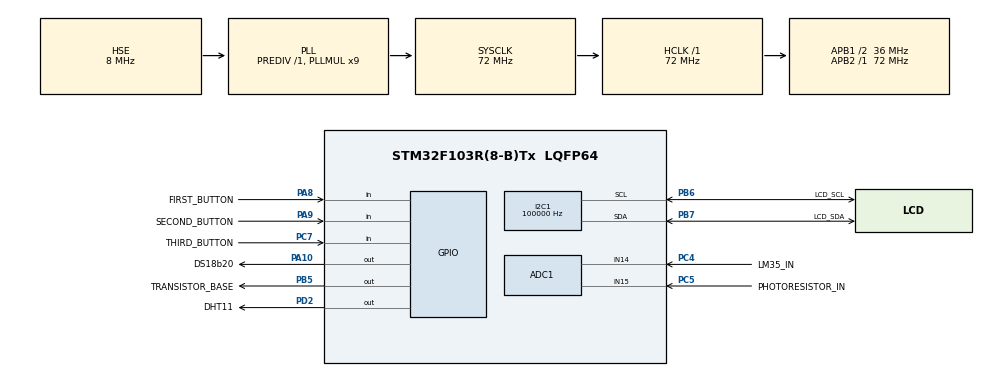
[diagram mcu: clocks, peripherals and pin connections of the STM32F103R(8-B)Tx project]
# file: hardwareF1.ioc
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ADC1.Channel-2\#ChannelRegularConversion=ADC_CHANNEL_14
ADC1.Channel-3\#ChannelRegularConversion=ADC_CHANNEL_TEMPSENSOR
ADC1.Channel-4\#ChannelRegularConversion=ADC_CHANNEL_15
ADC1.ContinuousConvMode=ENABLE
ADC1.DataAlign=ADC_DATAALIGN_RIGHT
ADC1.NbrOfConversion=3
ADC1.NbrOfConversionFlag=1
ADC1.Rank-2\#ChannelRegularConversion=1
ADC1.Rank-3\#ChannelRegularConversion=2
ADC1.Rank-4\#ChannelRegularConversion=3
ADC1.SamplingTime-2\#ChannelRegularConversion=ADC_SAMPLETIME_239CYCLES_5
ADC1.SamplingTime-3\#ChannelRegularConversion=ADC_SAMPLETIME_239CYCLES_5
ADC1.SamplingTime-4\#ChannelRegularConversion=ADC_SAMPLETIME_239CYCLES_5
ADC1.master=1
Dma.ADC1.0.Direction=DMA_PERIPH_TO_MEMORY
Dma.ADC1.0.Instance=DMA1_Channel1
Dma.ADC1.0.MemDataAlignment=DMA_MDATAALIGN_WORD
Dma.ADC1.0.MemInc=DMA_MINC_ENABLE
Dma.ADC1.0.Mode=DMA_CIRCULAR
Dma.ADC1.0.PeriphDataAlignment=DMA_PDATAALIGN_HALFWORD
Dma.ADC1.0.PeriphInc=DMA_PINC_DISABLE
Dma.ADC1.0.Priority=DMA_PRIORITY_LOW
Dma.Request0=ADC1
I2C1.AddressingMode=I2C_ADDRESSINGMODE_7BIT
I2C1.ClockSpeed=100000
I2C1.I2C_Mode=I2C_Standard
Mcu.Family=STM32F1
Mcu.Name=STM32F103R(8-B)Tx
Mcu.Package=LQFP64
NVIC.DMA1_Channel1_IRQn=true\:0\:0\:false\:false\:true\:false\:true
NVIC.PriorityGroup=NVIC_PRIORITYGROUP_4
NVIC.TIM3_IRQn=true\:0\:0\:false\:false\:true\:true\:true
PA10.GPIO_Label=DS18b20
PA10.Signal=GPIO_Output
PA13.Mode=JTAG_4_pins
PA13.Signal=SYS_JTMS-SWDIO
PA14.Mode=JTAG_4_pins
PA14.Signal=SYS_JTCK-SWCLK
PA15.Mode=JTAG_4_pins
PA15.Signal=SYS_JTDI
PA8.GPIO_Label=FIRST_BUTTON
PA8.Signal=GPIO_Input
PA9.GPIO_Label=SECOND_BUTTON
PA9.Signal=GPIO_Input
PB3.Mode=JTAG_4_pins
PB3.Signal=SYS_JTDO-TRACESWO
PB5.GPIO_Label=TRANSISTOR_BASE
PB5.Signal=GPIO_Output
PB6.GPIO_Label=LCD_SCL
PB6.Mode=I2C
PB6.Signal=I2C1_SCL
PB7.GPIO_Label=LCD_SDA
PB7.Mode=I2C
PB7.Signal=I2C1_SDA
PC4.GPIO_Label=LM35_IN
PC4.Signal=ADCx_IN14
PC5.GPIO_Label=PHOTORESISTOR_IN
PC5.Signal=ADCx_IN15
PC7.GPIO_Label=THIRD_BUTTON
PC7.Signal=GPIO_Input
PD0-OSC_IN.Mode=HSE-External-Oscillator
PD0-OSC_IN.Signal=RCC_OSC_IN
PD1-OSC_OUT.Mode=HSE-External-Oscillator
PD1-OSC_OUT.Signal=RCC_OSC_OUT
PD2.GPIO_Label=DHT11
PD2.GPIO_ModeDefaultOutputPP=GPIO_MODE_OUTPUT_OD
PD2.GPIO_PuPd=GPIO_PULLUP
PD2.Signal=GPIO_Output
ProjectManager.HeapSize=0x200
ProjectManager.StackSize=0x400
ProjectManager.TargetToolchain=STM32CubeIDE
RCC.ADCPresc=RCC_ADCPCLK2_DIV6
RCC.AHBFreq_Value=72000000
RCC.APB1CLKDivider=RCC_HCLK_DIV2
RCC.APB1Freq_Value=36000000
RCC.APB1TimFreq_Value=72000000
RCC.APB2Freq_Value=72000000
RCC.APB2TimFreq_Value=72000000
RCC.HCLKFreq_Value=72000000
RCC.PLLMUL=RCC_PLL_MUL9
RCC.PLLSourceVirtual=RCC_PLLSOURCE_HSE
RCC.SYSCLKFreq_VALUE=72000000
RCC.SYSCLKSource=RCC_SYSCLKSOURCE_PLLCLK
RCC.USBFreq_Value=72000000
SH.ADCx_IN14.0=ADC1_IN14,IN14
SH.ADCx_IN15.0=ADC1_IN15,IN15
TIM2.AutoReloadPreload=TIM_AUTORELOAD_PRELOAD_ENABLE
TIM2.Period=65535
TIM2.Prescaler=71
TIM3.AutoReloadPreload=TIM_AUTORELOAD_PRELOAD_ENABLE
TIM3.Period=999
TIM3.Prescaler=71
VP_ADC1_TempSens_Input.Mode=IN-TempSens
VP_TIM2_VS_ClockSourceINT.Mode=Internal
VP_TIM3_VS_ClockSourceINT.Mode=Internal
board=custom

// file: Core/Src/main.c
/* USER CODE BEGIN Header */
/**
  ******************************************************************************
  * @file           : main.c
  * @brief          : Main program body
  ******************************************************************************
  * @attention
  *
  * <h2><center>&copy; Copyright (c) 2020 STMicroelectronics.
  * All rights reserved.</center></h2>
  *
  * This software component is licensed by ST under BSD 3-Clause license,
  * the "License"; You may not use this file except in compliance with the
  * License. You may obtain a copy of the License at:
  *                        opensource.org/licenses/BSD-3-Clause
  *
  ******************************************************************************
  */
/*PINS AND TIMERS CONFIGURATION
 *
 * TIM3- uzywany do obliczenia opóxnienia 1 us
 * TIM2 - timer dla systemowego czasu (przerwanie 10 ms)
 * PC13 - niebieski, wbudowany przycisk
 * PC1 (A4) - wejście analogowe dla LM35
 * PA5 (6) - wyjście dla wbudowanej diody
 * PB9 (SDA) - SDA dla LCD 1602
 * PB8 (SCL) - SCL dla LCD 1602
 *
 * */
/* USER CODE END Header */

#include "main.h"

/* USER CODE BEGIN Includes */
#include "timer.h"
#include "HAL_Functions.h"
#include "temperature.h"
#include "main_loop.h"
/* USER CODE END Includes */

ADC_HandleTypeDef hadc1;
DMA_HandleTypeDef hdma_adc1;

I2C_HandleTypeDef hi2c1;

TIM_HandleTypeDef htim2;
TIM_HandleTypeDef htim3;

void SystemClock_Config(void);
static void MX_GPIO_Init(void);
static void MX_DMA_Init(void);
static void MX_TIM2_Init(void);
static void MX_TIM3_Init(void);
static void MX_I2C1_Init(void);
static void MX_ADC1_Init(void);

int main(void)
{

  /* MCU Configuration--------------------------------------------------------*/

  /* Reset of all peripherals, Initializes the Flash interface and the Systick. */
  HAL_Init();

  /* Configure the system clock */
  SystemClock_Config();

  /* Initialize all configured peripherals */
  MX_GPIO_Init();
  MX_DMA_Init();
  MX_TIM2_Init();
  MX_TIM3_Init();
  MX_I2C1_Init();
  MX_ADC1_Init();
  /* USER CODE BEGIN 2 */
  Initialize();
  /* USER CODE END 2 */

  /* Infinite loop */
  /* USER CODE BEGIN WHILE */
  while (1)
  {
	  Main_Loop();
    /* USER CODE END WHILE */

  }
}

void SystemClock_Config(void)
{
  RCC_OscInitTypeDef RCC_OscInitStruct = {0};
  RCC_ClkInitTypeDef RCC_ClkInitStruct = {0};
  RCC_PeriphCLKInitTypeDef PeriphClkInit = {0};

  /** Initializes the CPU, AHB and APB busses clocks
  */
  RCC_OscInitStruct.OscillatorType = RCC_OSCILLATORTYPE_HSE;
  RCC_OscInitStruct.HSEState = RCC_HSE_ON;
  RCC_OscInitStruct.HSEPredivValue = RCC_HSE_PREDIV_DIV1;
  RCC_OscInitStruct.HSIState = RCC_HSI_ON;
  RCC_OscInitStruct.PLL.PLLState = RCC_PLL_ON;
  RCC_OscInitStruct.PLL.PLLSource = RCC_PLLSOURCE_HSE;
  RCC_OscInitStruct.PLL.PLLMUL = RCC_PLL_MUL9;
  if (HAL_RCC_OscConfig(&RCC_OscInitStruct) != HAL_OK)
  {
    Error_Handler();
  }
  /** Initializes the CPU, AHB and APB busses clocks
  */
  RCC_ClkInitStruct.ClockType = RCC_CLOCKTYPE_HCLK|RCC_CLOCKTYPE_SYSCLK
                              |RCC_CLOCKTYPE_PCLK1|RCC_CLOCKTYPE_PCLK2;
  RCC_ClkInitStruct.SYSCLKSource = RCC_SYSCLKSOURCE_PLLCLK;
  RCC_ClkInitStruct.AHBCLKDivider = RCC_SYSCLK_DIV1;
  RCC_ClkInitStruct.APB1CLKDivider = RCC_HCLK_DIV2;
  RCC_ClkInitStruct.APB2CLKDivider = RCC_HCLK_DIV1;

  if (HAL_RCC_ClockConfig(&RCC_ClkInitStruct, FLASH_LATENCY_2) != HAL_OK)
  {
    Error_Handler();
  }
  PeriphClkInit.PeriphClockSelection = RCC_PERIPHCLK_ADC;
  PeriphClkInit.AdcClockSelection = RCC_ADCPCLK2_DIV6;
  if (HAL_RCCEx_PeriphCLKConfig(&PeriphClkInit) != HAL_OK)
  {
    Error_Handler();
  }
}

static void MX_ADC1_Init(void)
{

  ADC_ChannelConfTypeDef sConfig = {0};

  /** Common config
  */
  hadc1.Instance = ADC1;
  hadc1.Init.ScanConvMode = ADC_SCAN_ENABLE;
  hadc1.Init.ContinuousConvMode = ENABLE;
  hadc1.Init.DiscontinuousConvMode = DISABLE;
  hadc1.Init.ExternalTrigConv = ADC_SOFTWARE_START;
  hadc1.Init.DataAlign = ADC_DATAALIGN_RIGHT;
  hadc1.Init.NbrOfConversion = 2;
  if (HAL_ADC_Init(&hadc1) != HAL_OK)
  {
    Error_Handler();
  }
  /** Configure Regular Channel
  */
  sConfig.Channel = ADC_CHANNEL_14;
  sConfig.Rank = ADC_REGULAR_RANK_1;
  sConfig.SamplingTime = ADC_SAMPLETIME_239CYCLES_5;
  if (HAL_ADC_ConfigChannel(&hadc1, &sConfig) != HAL_OK)
  {
    Error_Handler();
  }
  /** Configure Regular Channel
  */
  sConfig.Channel = ADC_CHANNEL_TEMPSENSOR;
  sConfig.Rank = ADC_REGULAR_RANK_2;
  if (HAL_ADC_ConfigChannel(&hadc1, &sConfig) != HAL_OK)
  {
    Error_Handler();
  }

}

static void MX_I2C1_Init(void)
{

  hi2c1.Instance = I2C1;
  hi2c1.Init.ClockSpeed = 100000;
  hi2c1.Init.DutyCycle = I2C_DUTYCYCLE_2;
  hi2c1.Init.OwnAddress1 = 0;
  hi2c1.Init.AddressingMode = I2C_ADDRESSINGMODE_7BIT;
  hi2c1.Init.DualAddressMode = I2C_DUALADDRESS_DISABLE;
  hi2c1.Init.OwnAddress2 = 0;
  hi2c1.Init.GeneralCallMode = I2C_GENERALCALL_DISABLE;
  hi2c1.Init.NoStretchMode = I2C_NOSTRETCH_DISABLE;
  if (HAL_I2C_Init(&hi2c1) != HAL_OK)
  {
    Error_Handler();
  }

}

static void MX_TIM2_Init(void)
{

  TIM_ClockConfigTypeDef sClockSourceConfig = {0};
  TIM_MasterConfigTypeDef sMasterConfig = {0};

  htim2.Instance = TIM2;
  htim2.Init.Prescaler = 71;
  htim2.Init.CounterMode = TIM_COUNTERMODE_UP;
  htim2.Init.Period = 65535;
  htim2.Init.ClockDivision = TIM_CLOCKDIVISION_DIV1;
  htim2.Init.AutoReloadPreload = TIM_AUTORELOAD_PRELOAD_ENABLE;
  if (HAL_TIM_Base_Init(&htim2) != HAL_OK)
  {
    Error_Handler();
  }
  sClockSourceConfig.ClockSource = TIM_CLOCKSOURCE_INTERNAL;
  if (HAL_TIM_ConfigClockSource(&htim2, &sClockSourceConfig) != HAL_OK)
  {
    Error_Handler();
  }
  sMasterConfig.MasterOutputTrigger = TIM_TRGO_RESET;
  sMasterConfig.MasterSlaveMode = TIM_MASTERSLAVEMODE_DISABLE;
  if (HAL_TIMEx_MasterConfigSynchronization(&htim2, &sMasterConfig) != HAL_OK)
  {
    Error_Handler();
  }
  /* USER CODE BEGIN TIM2_Init 2 */
  HAL_TIM_Base_Start_IT(&htim2);
  /* USER CODE END TIM2_Init 2 */

}

static void MX_TIM3_Init(void)
{

  TIM_ClockConfigTypeDef sClockSourceConfig = {0};
  TIM_MasterConfigTypeDef sMasterConfig = {0};

  htim3.Instance = TIM3;
  htim3.Init.Prescaler = 71;
  htim3.Init.CounterMode = TIM_COUNTERMODE_UP;
  htim3.Init.Period = 999;
  htim3.Init.ClockDivision = TIM_CLOCKDIVISION_DIV1;
  htim3.Init.AutoReloadPreload = TIM_AUTORELOAD_PRELOAD_ENABLE;
  if (HAL_TIM_Base_Init(&htim3) != HAL_OK)
  {
    Error_Handler();
  }
  sClockSourceConfig.ClockSource = TIM_CLOCKSOURCE_INTERNAL;
  if (HAL_TIM_ConfigClockSource(&htim3, &sClockSourceConfig) != HAL_OK)
  {
    Error_Handler();
  }
  sMasterConfig.MasterOutputTrigger = TIM_TRGO_RESET;
  sMasterConfig.MasterSlaveMode = TIM_MASTERSLAVEMODE_DISABLE;
  if (HAL_TIMEx_MasterConfigSynchronization(&htim3, &sMasterConfig) != HAL_OK)
  {
    Error_Handler();
  }

}

static void MX_DMA_Init(void)
{

  /* DMA controller clock enable */
  __HAL_RCC_DMA1_CLK_ENABLE();

  /* DMA interrupt init */
  /* DMA1_Channel1_IRQn interrupt configuration */
  HAL_NVIC_SetPriority(DMA1_Channel1_IRQn, 0, 0);
  HAL_NVIC_EnableIRQ(DMA1_Channel1_IRQn);

}

static void MX_GPIO_Init(void)
{
  GPIO_InitTypeDef GPIO_InitStruct = {0};

  /* GPIO Ports Clock Enable */
  __HAL_RCC_GPIOD_CLK_ENABLE();
  __HAL_RCC_GPIOC_CLK_ENABLE();
  __HAL_RCC_GPIOA_CLK_ENABLE();
  __HAL_RCC_GPIOB_CLK_ENABLE();

  /*Configure GPIO pin Output Level */
  HAL_GPIO_WritePin(DS18b20_GPIO_Port, DS18b20_Pin, GPIO_PIN_RESET);

  /*Configure GPIO pin Output Level */
  HAL_GPIO_WritePin(DHT11_GPIO_Port, DHT11_Pin, GPIO_PIN_RESET);

  /*Configure GPIO pin Output Level */
  HAL_GPIO_WritePin(TRANSISTOR_BASE_GPIO_Port, TRANSISTOR_BASE_Pin, GPIO_PIN_RESET);

  /*Configure GPIO pin : THIRD_BUTTON_Pin */
  GPIO_InitStruct.Pin = THIRD_BUTTON_Pin;
  GPIO_InitStruct.Mode = GPIO_MODE_IT_RISING;
  GPIO_InitStruct.Pull = GPIO_NOPULL;
  HAL_GPIO_Init(THIRD_BUTTON_GPIO_Port, &GPIO_InitStruct);

  /*Configure GPIO pins : FIRST_BUTTON_Pin SECOND_BUTTON_Pin */
  GPIO_InitStruct.Pin = FIRST_BUTTON_Pin|SECOND_BUTTON_Pin;
  GPIO_InitStruct.Mode = GPIO_MODE_IT_RISING;
  GPIO_InitStruct.Pull = GPIO_NOPULL;
  HAL_GPIO_Init(GPIOA, &GPIO_InitStruct);

  /*Configure GPIO pin : DS18b20_Pin */
  GPIO_InitStruct.Pin = DS18b20_Pin;
  GPIO_InitStruct.Mode = GPIO_MODE_OUTPUT_PP;
  GPIO_InitStruct.Pull = GPIO_NOPULL;
  GPIO_InitStruct.Speed = GPIO_SPEED_FREQ_LOW;
  HAL_GPIO_Init(DS18b20_GPIO_Port, &GPIO_InitStruct);

  /*Configure GPIO pin : DHT11_Pin */
  GPIO_InitStruct.Pin = DHT11_Pin;
  GPIO_InitStruct.Mode = GPIO_MODE_OUTPUT_PP;
  GPIO_InitStruct.Pull = GPIO_NOPULL;
  GPIO_InitStruct.Speed = GPIO_SPEED_FREQ_LOW;
  HAL_GPIO_Init(DHT11_GPIO_Port, &GPIO_InitStruct);

  /*Configure GPIO pin : TRANSISTOR_BASE_Pin */
  GPIO_InitStruct.Pin = TRANSISTOR_BASE_Pin;
  GPIO_InitStruct.Mode = GPIO_MODE_OUTPUT_PP;
  GPIO_InitStruct.Pull = GPIO_NOPULL;
  GPIO_InitStruct.Speed = GPIO_SPEED_FREQ_LOW;
  HAL_GPIO_Init(TRANSISTOR_BASE_GPIO_Port, &GPIO_InitStruct);

}

/* USER CODE BEGIN 4 */
void HAL_GPIO_EXTI_Callback(uint16_t GPIO_Pin)
{
	GPIOs_Callback_Service(GPIO_Pin);
}

void HAL_TIM_PeriodElapsedCallback(TIM_HandleTypeDef *htim)
{
	Timers_Callback_Service(htim);
}

void HAL_ADC_ConvCpltCallback(ADC_HandleTypeDef *hadc)
{
	Temperature_Service(HAL_ADC_GetValue(hadc));
}

/* USER CODE END 4 */

void Error_Handler(void)
{
}

/************************ (C) COPYRIGHT STMicroelectronics *****END OF FILE****/
